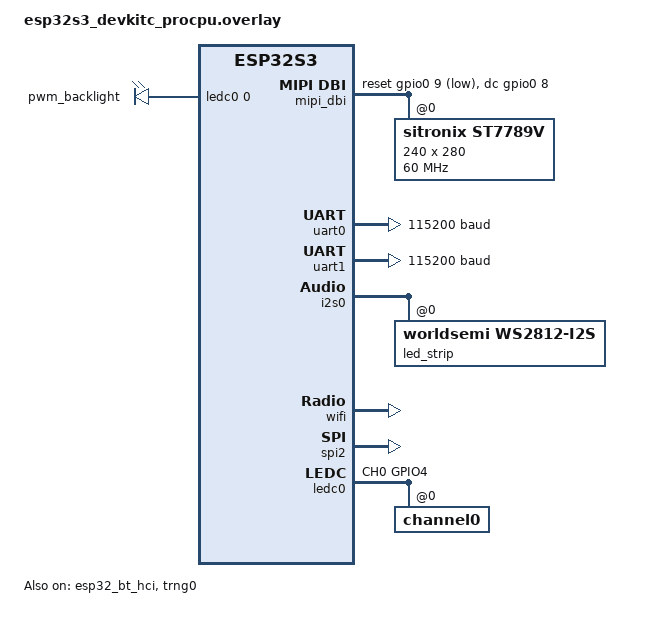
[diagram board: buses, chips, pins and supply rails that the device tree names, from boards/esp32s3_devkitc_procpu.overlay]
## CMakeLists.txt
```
# SPDX-License-Identifier: Apache-2.0

# 设定CMake最低版本门槛
cmake_minimum_required(VERSION 3.20.0)

# 告诉 Zephyr 在哪里找自定义的设备树绑定文件
# list(APPEND DTC_OVERLAY_FILE "${CMAKE_CURRENT_SOURCE_DIR}/esp32s3_devkitc_procpu.overlay")

# 设置自定义设备树绑定文件 (Bindings) 的搜索根目录。
# ${CMAKE_CURRENT_SOURCE_DIR} 指的是当前 CMakeLists.txt 所在的文件夹路径。
# 这行代码告诉 Zephyr 编译器：“除了去内核找硬件定义，也去我当前的项目目录下找找（通常是 dts/bindings 目录）”。
# 这样你写的 custom,sh1106.yaml 才能被系统识别。
set(DTS_ROOT ${CMAKE_CURRENT_SOURCE_DIR})

# 引入 Zephyr 编译框架的核心包。
# REQUIRED 表示这个包是必须的，找不到就直接报错停止。
# HINTS $ENV{ZEPHYR_BASE} 是给编译器一个“线索”，告诉它去环境变量 ZEPHYR_BASE 指向的路径找 Zephyr。
# 执行完这一行后，Zephyr 的所有编译规则、库文件、驱动框架都会被加载进你的项目中。
find_package(Zephyr REQUIRED HINTS $ENV{ZEPHYR_BASE})

# 定义当前项目的名称。
# 这里将项目命名为 "application"。这个名字会影响最终生成的二进制文件名（如 application.elf）。
# 它必须放在 find_package(Zephyr ...) 之后，因为 Zephyr 需要先初始化环境才能支持后续的项目定义。
project(application)

# 添加应用程序私有的头文件目录
# PRIVATE 表示这个 include 路径只对当前 app target 有效
target_include_directories(app PRIVATE
    include
    drivers/include
)

# 添加所有源文件到应用程序目标
target_sources(app PRIVATE
    src/main.c
    # src/memory_thread.c
    src/led_thread.c
    src/button_thread.c
    # src/bt_beacon_thread.c
    # src/bt_ibeacon_thread.c
    # src/bt_broadcaster_thread.c
    # src/bt_bthome_sensor_thread.c
    # src/bt_peripheral_thread.c
    src/bt_peripheral_nus_thread.c
    src/lcd_lvgl_thread.c
    src/wifi_weather_thread.c
    src/fonts/weather_chinese_font.c
    src/images/zephyr_200x116.c
    src/images/cyberpunk_240x280.c
    # src/lvgl_benchmark_thread.c        # [可选] LVGL 官方性能测试 (需同时启用 prj.conf 中的 CONFIG_LV_USE_DEMO_BENCHMARK)
)

# [LVGL Widgets Demo] 收集上游 LVGL 仓库中的 demo 源文件
# Zephyr 的 LVGL 模块只编译核心库, demo 的 .c 文件需要手动加入 target_sources
# lv_demos.c 是伞形文件, 根据 CONFIG_LV_USE_DEMO_WIDGETS 用 #if 条件包含各子文件
# file(GLOB_RECURSE LVGL_WIDGETS_SOURCES
#     # [伞形文件] 根据 Kconfig 决定编译哪些 demo (必须首先包含)
#     ${ZEPHYR_LVGL_MODULE_DIR}/demos/lv_demos.c
#     # [Widgets 主文件] 创建 TabView 容器 + 4 个 Tab 页面 + 自动幻灯片定时器
#     ${ZEPHYR_LVGL_MODULE_DIR}/demos/widgets/lv_demo_widgets.c
#     # [4 个子页面] 每个 Tab 对应一个独立的功能页面
#     ${ZEPHYR_LVGL_MODULE_DIR}/demos/widgets/lv_demo_widgets_shop.c
#     ${ZEPHYR_LVGL_MODULE_DIR}/demos/widgets/lv_demo_widgets_analytics.c
#     ${ZEPHYR_LVGL_MODULE_DIR}/demos/widgets/lv_demo_widgets_profile.c
#     ${ZEPHYR_LVGL_MODULE_DIR}/demos/widgets/lv_demo_widgets_components.c
#     # [图片资源] 预编译的 RGBA 像素数组, 链接到 Flash .rodata 段
#     ${ZEPHYR_LVGL_MODULE_DIR}/demos/widgets/assets/img_lvgl_logo.c
#     ${ZEPHYR_LVGL_MODULE_DIR}/demos/widgets/assets/img_clothes.c
#     ${ZEPHYR_LVGL_MODULE_DIR}/demos/widgets/assets/img_demo_widgets_avatar.c
#     ${ZEPHYR_LVGL_MODULE_DIR}/demos/widgets/assets/img_demo_widgets_needle.c
# )
# target_sources(app PRIVATE ${LVGL_WIDGETS_SOURCES})

# (可选) 链接所需的 Zephyr 库
# 正确的链接方式：只需要链接到 'zephyr' 目标
# target_link_libraries(app PRIVATE
#     zephyr
# )
```

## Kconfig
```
# ESP32-S3 DevKitC 应用级 Kconfig 入口
#
# 此文件作为 Zephyr Kconfig 的主入口点，在引入 Zephyr 官方配置后
# 提供应用级的 Kconfig 选项覆盖。
#
# 注意：ESP32-S3 (Xtensa) 架构默认不选中 HAS_FLASH_LOAD_OFFSET，
# 但 MCUboot 集成需要通过 USE_DT_CODE_PARTITION 来获取代码分区偏移。
# 这里参考 Telink TLSR951X 的做法添加默认值。

source "Kconfig.zephyr"

# 工作区修复：Xtensa (ESP32-S3) 架构缺少 HAS_FLASH_LOAD_OFFSET
# 当启用 MCUboot 时，BOOTLOADER_MCUBOOT 会 select USE_DT_CODE_PARTITION，
# 但 USE_DT_CODE_PARTITION 定义在 if HAS_FLASH_LOAD_OFFSET 条件块中。
# 此默认值确保 MCUboot 模式下 HAS_FLASH_LOAD_OFFSET 自动为 y。
config HAS_FLASH_LOAD_OFFSET
	default y if BOOTLOADER_MCUBOOT
```

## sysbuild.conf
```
# ==============================================================================
# SYSBUILD 全局多镜像组织配置文件
# ==============================================================================

# 告诉系统我们要启用 MCUboot 引导
SB_CONFIG_BOOTLOADER_MCUBOOT=y
```

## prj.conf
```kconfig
#
# Kernel & System (内核与系统基础)
#
# 定义系统时钟滴答的频率
CONFIG_SYS_CLOCK_TICKS_PER_SEC=1000
# 详细注释：v4.4.0 推荐使用 picolibc 以获得更小的 Flash 占用
CONFIG_PICOLIBC=y
# LVGL初始化或文件系统操作会复用main stack，因此需要增加 main stack size
CONFIG_MAIN_STACK_SIZE=6144
# 开启 Zephyr 的输入子系统
CONFIG_INPUT=y
# 初始化任务栈（用特定字节填充，用于监测栈使用量）
CONFIG_INIT_STACKS=y

#
# ==========================================================
# 第一部分：Console (控制台) - 解决“信息从哪发出来”
# ==========================================================
# 启用控制台基础功能
CONFIG_CONSOLE=y
# 启用早期控制台支持（内核启动初期的日志输出）
CONFIG_EARLY_CONSOLE=y

# 【关键点】必须为 y！
# 它是内核启动早期（Shell还没启动时）打印 Zephyr 版本信息的唯一通道。
# 如果设为 n，你将看不到 "*** Booting Zephyr OS ***" 这一行。
CONFIG_UART_CONSOLE=y

# 允许 printk 函数将信息发送到控制台
CONFIG_STDOUT_CONSOLE=y

# ==========================================================
# 第二部分：Logging (日志) - 解决“系统发生了什么”
# ==========================================================
# 启用日志系统
CONFIG_LOG=y

# 设置日志的显示模式
# 由于我们要用 Shell 来显示日志，所以禁用掉原始的 UART 直接输出模式，
# 防止日志和 Shell 的字符在屏幕上打架（乱码）。
CONFIG_LOG_BACKEND_UART=n

# 允许 printk 输出的信息也被当作日志处理
CONFIG_LOG_PRINTK=y

# 日志级别设置（4 是最高级别 INFO，能看到大部分信息）
CONFIG_LOG_MAX_LEVEL=4
CONFIG_LOG_DEFAULT_LEVEL=3

# ==========================================================
# 第三部分：Shell (外壳) - 解决“如何与开发板交互”
# ==========================================================
# 启用 Shell 功能
CONFIG_SHELL=y
CONFIG_SHELL_BACKENDS=y

# Shell 命令行线程栈大小
CONFIG_SHELL_STACK_SIZE=6144

# 启用串口作为 Shell 的后端（让你可以通过串口助手输入命令）
CONFIG_SHELL_BACKEND_SERIAL=y

# 启用 Shell 的日志后端
# 作用：让 Shell 接管 Log 系统的输出。
# 开启后，当系统产生日志时，Shell 会整齐地把它打印出来，
# 并且不会打断你正在输入的命令行（它会自动处理换行和光标）。
CONFIG_SHELL_LOG_BACKEND=y

# 设置 Shell 提示符，你在串口看到的就会是 my_board:~$
CONFIG_SHELL_PROMPT_UART="zephyr:~$ "

# 启用 HEX 文件输出，解决 west flash --runner openocd 的报错
CONFIG_BUILD_OUTPUT_HEX=y

#
# Core Drivers: Serial/UART (核心驱动：串行/UART)
#
# 启用串行子系统
CONFIG_SERIAL=y

# 启用浮点支持，以便在日志中打印浮点数
CONFIG_CBPRINTF_FP_SUPPORT=y

#
# 启用 SPI RAM 支持
# 
# 1. 开启外部 RAM 总支持
CONFIG_ESP_SPIRAM=y
# 2. 必须指定是八线(Octal)模式（16MB 型号通常是 Octal 1.8V）
CONFIG_SPIRAM_MODE_OCT=y
# 3. 设置速度（80MHz 是常见的安全选择，160MHz 可能不稳定）
CONFIG_SPIRAM_SPEED_80M=y
# 3. 设置容量 (16MB = 16777216 字节)
# CONFIG_ESP_SPIRAM_SIZE=16777216
# 4. 将 SPI RAM 用作系统内存的一部分（启用后，malloc 等函数可以使用 SPI RAM）
# CONFIG_ESP_SPIRAM_HEAP_SIZE=8388608
# 6. 可选：启动时进行内存测试，确保硬件连接没问题
# CONFIG_ESP_SPIRAM_MEMTEST=y

# 开启堆内存运行时状态统计功能（不开启的话，sys_heap_runtime_stats_get 会无法获取数据）
CONFIG_SYS_HEAP_RUNTIME_STATS=y

# 
# MCUboot 核心引导配置
# 
# 告诉 Zephyr 内核：当前应用程序是运行在 MCUboot 引导程序之上的
# 开启后，系统会自动处理好固件在 Flash 中的地址偏移（例如自动偏移到 0x20000）
# CONFIG_BOOTLOADER_MCUBOOT=y

# 
# 底层 Flash 驱动与存储支持（固件管理器的依赖项）
# 
# 开启物理 Flash 的底层驱动支持
CONFIG_FLASH=y
# 开启 Flash 的页布局（Page Layout）支持，以便系统能按块擦写 Flash
CONFIG_FLASH_PAGE_LAYOUT=y
# 开启流式 Flash 写入驱动（重要！用来彻底解决之前 STREAM_FLASH=n 导致的警告）
CONFIG_STREAM_FLASH=y
# 开启 Flash 地图映射管理，用于精准识别存储分区（Slot 0 / Slot 1）
CONFIG_FLASH_MAP=y

# 
# 固件管理器与 MCUboot 运行时联动
# 
# 开启应用层的固件镜像管理器（用于读取/验证固件的版本头信息）
CONFIG_IMG_MANAGER=y
# 开启专属于 MCUboot 的镜像管理实现（解决 choice 选项悬空以及 FOOTER_SIZE 警告）
CONFIG_MCUBOOT_IMG_MANAGER=y

# 
# 关闭保守的自动检测，榨干 32MB 八线 Flash 的极限性能
# 
# 关闭自动检测（省下 900 字节 IRAM，且解锁 DTR 限制）
CONFIG_ESPTOOLPY_FLASH_MODE_AUTO_DETECT=n
# 强制开启八线Octal Flash支持
CONFIG_ESPTOOLPY_OCT_FLASH=y
# 强制开启最高速的 DTR（双倍速率）采样模式
CONFIG_ESPTOOLPY_FLASH_SAMPLE_MODE_DTR=y
# 强制指定 Flash 大小为 32MB
CONFIG_ESPTOOLPY_FLASHSIZE_32MB=y

#
# Core Drivers: DMA (直接内存访问)
#
# 启用 DMA 核心支持
CONFIG_DMA=y

#
# Core Drivers: GPIO (通用输入/输出)
#
# 启用 GPIO 核心支持
CONFIG_GPIO=y

#
# Core Drivers: I2C
#
# 启用 I2C 核心支持
# CONFIG_I2C=y
# 开启软件模拟 I2C 驱动
# CONFIG_I2C_GPIO=y

#
# Core Drivers: Standard SPI
#
# 启用标准 SPI 核心支持 (如果需要连接 SPI 传感器/屏幕)
CONFIG_SPI=y
# 注意: SPI2 DMA (GDMA) 已在 overlay 中关闭 — 开启后导致黑屏+串口失效
# 原因可能是 GDMA 通道与 I2S0(Ch3) 的仲裁冲突, 或 PSRAM→GDMA→SPI2 路径问题
# 当前使用 CPU PIO 模式 (逐字节推 FIFO), 稳定性优先, 性能可通过 flush_thread 补偿
# CONFIG_SPI_ESP32_INTERRUPT=y

#
# Core Drivers: I2S (集成音频接口)
#
# I2S 用于 WS2812 LED strip 波形生成 (通过 worldsemi,ws2812-i2s 驱动)
CONFIG_I2S=y

#
# Core Drivers: PWM (脉宽调制)
#
CONFIG_PWM=y

#
# Core Drivers: RTC (实时时钟)
#
# 启用 RTC 核心支持
# CONFIG_RTC=y
# 启用 RTC 闹钟功能
# CONFIG_RTC_ALARM=y

#
# Core Drivers: LED (发光二极管)
#
# 启用 LED 核心驱动框架
# CONFIG_LED=y
CONFIG_LED_STRIP=y

# ==========================================================
# Core Drivers: Bluetooth (蓝牙)
# ==========================================================
# 启用蓝牙子系统
CONFIG_BT=y
# 启用安全管理协议
CONFIG_BT_SMP=y
# 配置为蓝牙广播角色
CONFIG_BT_BROADCASTER=y
# 配置为蓝牙外设角色
CONFIG_BT_PERIPHERAL=y
# 启用隐私功能
CONFIG_BT_PRIVACY=y

# 蓝牙设备名称
CONFIG_BT_DEVICE_NAME="ESP32S3_BLE"
# 允许动态修改名称
CONFIG_BT_DEVICE_NAME_DYNAMIC=y
# 动态名称最大长度（设置为纯数字）
CONFIG_BT_DEVICE_NAME_MAX=64
# 设备外观（833代表心率计）
CONFIG_BT_DEVICE_APPEARANCE=833

# 基础 GATT 服务
CONFIG_BT_DIS=y
CONFIG_BT_BAS=y
CONFIG_BT_HRS=y
CONFIG_BT_IAS=y
CONFIG_BT_CTS=y
CONFIG_BT_CTS_HELPER_API=y

# 启用 Zephyr 的 NUS（Nordic UART Service）蓝牙服务
CONFIG_BT_ZEPHYR_NUS=y

# 将 Host 层的连接发送上下文数量从默认值改为 12
CONFIG_BT_CONN_TX_MAX=12
# 建议同时将 ACL 缓存数量也对齐
CONFIG_BT_BUF_ACL_TX_COUNT=12

# 系统配置
# 增加工作队列栈大小（设置为纯数字）
CONFIG_SYSTEM_WORKQUEUE_STACK_SIZE=4096

# ==========================================================
# Core Drivers: NET (网络协议栈)
# ==========================================================
# 启用NET子系统

# 开启 Zephyr 核心网络通用协议栈支持
CONFIG_NETWORKING=y
# 开启测试用随机数生成器
CONFIG_TEST_RANDOM_GENERATOR=y

# 网络发送线程栈大小 (2048 字节)
CONFIG_NET_TX_STACK_SIZE=2048
# 网络接收线程栈大小 (2048 字节)
CONFIG_NET_RX_STACK_SIZE=2048

# 接收网络包结构体的最大数量
CONFIG_NET_PKT_RX_COUNT=10
# 发送网络包结构体的最大数量
CONFIG_NET_PKT_TX_COUNT=10
# 接收网络缓冲区的最大数量
CONFIG_NET_BUF_RX_COUNT=20
# 发送网络缓冲区的最大数量
CONFIG_NET_BUF_TX_COUNT=20
# 系统允许同时打开的最大网络上下文（套接字）数量
CONFIG_NET_MAX_CONTEXTS=10

# 开启 IPv4 协议支持（我们上网主力）
CONFIG_NET_IPV4=y
# 关闭 IPv6 协议支持（节省大量 RAM 空间！）
CONFIG_NET_IPV6=n
# 开启 TCP 传输层协议（用于后续 HTTP/MQTT）
CONFIG_NET_TCP=y
# 开启 DHCPv4 客户端（连接路由器后自动向其申请 IP）
CONFIG_NET_DHCPV4=y

# 开启网络 Shell 指令支持（如支持输入 net iface, net ping 等）
CONFIG_NET_SHELL=y
# 开启网络栈的内部日志输出输出
CONFIG_NET_LOG=y
# 开启网络流量统计统计（记录发了多少包，丢了多少包）
CONFIG_NET_STATISTICS=y
# 关闭定时自动在屏幕上打印统计报告
CONFIG_NET_STATISTICS_PERIODIC_OUTPUT=n

# 在新的锁设计中，向串口打印大量的扫描结果（WiFi Scan）会给系统的事件队列造成巨大的时间压力。
# 所以，在周围路由器非常密集的拥挤环境中，需要使用更高的超时时间和更大的队列深度。
# 事件队列超时时间放宽到 5000 毫秒
CONFIG_NET_MGMT_EVENT_QUEUE_TIMEOUT=5000
# 事件队列深度扩大到 16
CONFIG_NET_MGMT_EVENT_QUEUE_SIZE=16

# 开启动态域名解析功能（DNS Resolver）
CONFIG_DNS_RESOLVER=y
# 允许系统最多同时保存2个DNS服务器（一个主，一个备）
CONFIG_DNS_RESOLVER_MAX_SERVERS=2
# 允许通过 DHCP 自动从路由器获取 DNS 服务器的 IP地址
CONFIG_DNS_SERVER_IP_ADDRESSES=y

# ==========================================================
# Core Drivers: Wifi
# ==========================================================
# 启用Wifi子系统

# 开启底层 Wi-Fi 硬件驱动支持
CONFIG_WIFI=y
# 设置 Wi-Fi 日志级别为错误（只显示错误信息，减少日志干扰）
CONFIG_WIFI_LOG_LEVEL_ERR=y
# 启用 Wi-Fi Shell 命令，允许通过 Shell 交互式管理 Wi-Fi 连接（扫描、连接、状态查询等）
CONFIG_NET_L2_WIFI_SHELL=y

# ==========================================================
# Core Drivers: SNTP (简单网络时间协议)
# ==========================================================
# 启用 SNTP 客户端库（用于从 NTP 服务器获取精确的网络时间）
# SNTP 的超时时间在 C 代码中通过 sntp_ctx_obj.timeout 动态设置
CONFIG_SNTP=y

# ==========================================================
# Core Drivers: Socket DNS (增强 DNS 查询能力)
# ==========================================================
# 增加额外 DNS 查询次数 (类型为 int，取值 0~2)
# 当 DNS 响应只包含 CNAME 时，允许解析器额外发起查询以获取最终 A 记录
CONFIG_DNS_RESOLVER_ADDITIONAL_QUERIES=2

# ==========================================================
# Core Libraries: JSON (轻量级 JSON 解析库)
# ==========================================================
# 启用 Zephyr 内置 JSON 解析库（用于解析天气 API 返回的 JSON 响应）
CONFIG_JSON_LIBRARY=y

# Core dump 是在程序崩溃时保留的内存快照
# CONFIG_DEBUG_COREDUMP=y
# CONFIG_DEBUG_COREDUMP_BACKEND_LOGGING=y

#
# ==========================================================
# LCD & LVGL (液晶显示屏 + 图形界面)
# ==========================================================
# 启用显示子系统
CONFIG_DISPLAY=y
# 启用 MIPI DBI 模式 C (SPI 模拟) — 自动被 ST7789V 驱动选中
CONFIG_MIPI_DBI=y

# 启用 LVGL 图形库
CONFIG_LVGL=y
# 颜色深度使用 16 位 RGB565 (匹配 ST7789V 硬件格式)
CONFIG_LV_COLOR_DEPTH_16=y
# 启用 LVGL 内部日志
CONFIG_LV_USE_LOG=y
# LVGL 内存池大小 (从系统堆分配，用于 LVGL 内部对象管理)
# Widgets Demo 至少需要 38KB (编译器内置检查: LV_MEM_SIZE < 38KB 报错)
# 设为 48KB 留出安全余量, 内存池放在 PSRAM (CONFIG_LV_Z_MEMORY_POOL_CUSTOM_SECTION=y)
CONFIG_LV_Z_MEM_POOL_SIZE=65536
# ===== LVGL 渲染缓冲区 (性能关键) =====
# 渲染缓冲区 = 屏幕总像素的 100% (全帧缓冲)
# 240×280×2 字节 = 131KB 单缓冲, 262KB 双缓冲
# 放入 PSRAM (16MB) — 完全不占用宝贵的内部 SRAM
CONFIG_LV_Z_VDB_SIZE=100
# 双缓冲: LVGL 渲染到 buf0 的同时, SPI 从 buf1 刷屏
# 消除画面撕裂 (tearing), 是视觉流畅度的最大提升项
CONFIG_LV_Z_DOUBLE_VDB=y
# 缓冲区从静态数组分配 (编译时决定)
CONFIG_LV_Z_BUFFER_ALLOC_STATIC=y
# ★★★ 关键: 将渲染缓冲区放入 PSRAM ★★★
# ESP32-S3 default.ld 第 1049 行已内置: KEEP(*(.lvgl_buf*))
# 开启后 __attribute__((section(".lvgl_buf"))) → 链接器自动放入 ext_dram_seg
CONFIG_LV_Z_VDB_CUSTOM_SECTION=y
# ★★★ 关键: 将 LVGL 内存池放入 PSRAM ★★★
# ESP32-S3 default.ld 第 1051 行已内置: KEEP(*(.lvgl_heap*))
CONFIG_LV_Z_MEMORY_POOL_CUSTOM_SECTION=y
# 在应用启动前自动初始化 LVGL 库
CONFIG_LV_Z_AUTO_INIT=y

# ===== LVGL 独立渲染工作队列 (性能关键) =====
# 开启后 LVGL 在专用高优先级线程中运行 lv_timer_handler(),
# 应用线程不再需要手动调用, 且不会被低优先级任务阻塞
CONFIG_LV_Z_RUN_LVGL_ON_WORKQUEUE=y
# 工作队列优先级: 5 (高于大部分应用线程, 保证 UI 流畅)
CONFIG_LV_Z_LVGL_WORKQUEUE_PRIORITY=5
# 工作队列栈大小: 4096 (足够 LVGL 渲染使用)
CONFIG_LV_Z_LVGL_WORKQUEUE_STACK_SIZE=4096

# 启用 16 位颜色字节交换 (RGB565 格式)
# 【关键】ESP32 是小端序 (Little Endian)，而 ST7789 屏幕期望大端序 (Big Endian) 数据。
# 不开启此选项时：像素数据按 [高8位][低8位] 顺序发送，屏幕端解析颠倒 →
#                 现象：屏幕能显示图像，但颜色完全错误（红蓝颠倒、花屏、杂色）
# 开启此选项后：LVGL 在发送前自动交换每 2 字节的高低顺序 →
#                 发送 [低8位][高8位]，屏幕正确解析为 RGB565
# 总结：只要 SPI 屏颜色不对，第一个检查的就是这个选项！
CONFIG_LV_COLOR_16_SWAP=y

# ===== LVGL Widgets (按需启用，节约 Flash) =====
CONFIG_LV_USE_LABEL=y
CONFIG_LV_USE_BUTTON=y
CONFIG_LV_USE_IMAGE=y
CONFIG_LV_USE_CANVAS=y
CONFIG_LV_FONT_MONTSERRAT_14=y
# Widgets Demo 界面使用多种字号 (标题/正文/图表标注)
# Montserrat 字体族: 12=小字标签, 16=正文字号, 18/20=标题, 24=大标题
CONFIG_LV_FONT_MONTSERRAT_12=y
CONFIG_LV_FONT_MONTSERRAT_16=y
CONFIG_LV_FONT_MONTSERRAT_18=y
CONFIG_LV_FONT_MONTSERRAT_20=y
CONFIG_LV_FONT_MONTSERRAT_24=y

# [赛博朋克时钟] 48号巨字时间 + 28号温度数字
CONFIG_LV_FONT_MONTSERRAT_28=y
CONFIG_LV_FONT_MONTSERRAT_48=y

# [已替换] 改用自定义 weather_chinese_font (src/fonts/weather_chinese_font.c)
# CONFIG_LV_FONT_SOURCE_HAN_SANS_SC_16_CJK=y

# ===== LVGL 官方 Demo 构建 =====
# LV_BUILD_DEMOS 是编译 lv_demos.c 的门控开关 (伞形文件)
CONFIG_LV_BUILD_DEMOS=y
# Widgets Demo: 4 个 Tab 页 (Shop/Analytics/Profile/Components)
# 自动 8 秒轮播切换, 是 LVGL 9 自带的视觉最丰富的官方 Demo
CONFIG_LV_USE_DEMO_WIDGETS=y
# 系统监控: 为 perf monitor 提供真实 CPU 空闲率数据
# 如果不启用, perf monitor 会回退到测量 lv_timer_handler 耗时来估算 CPU
CONFIG_LV_USE_SYSMON=y
# [已关闭] 右下角 FPS/CPU 性能监视器 (赛博朋克时钟不需要)
# CONFIG_LV_USE_PERF_MONITOR=y
# 刷新周期: 默认 33ms(30FPS) → 10ms(100FPS) 解除帧率软上限
CONFIG_LV_DEF_REFR_PERIOD=10
# 独立刷新线程: 渲染和 SPI 刷屏并行, 消除等待
CONFIG_LV_Z_FLUSH_THREAD=y
```

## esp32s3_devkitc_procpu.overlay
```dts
/* esp32s3_devkitc_procpu.overlay */

/* 直接包含适配 16MB Flash + 8MB PSRAM 的定义 */
// #include <espressif/esp32s3/esp32s3_wroom_n16r8.dtsi>

/* 包含必要的头文件，这些头文件里定义了硬件信号 ID */
#include <espressif/esp32s3/esp32s3_common.dtsi>
#include <zephyr/dt-bindings/pinctrl/esp32s3-pinctrl.h>
#include <zephyr/dt-bindings/pinctrl/esp32s3-gpio-sigmap.h>
#include <zephyr/dt-bindings/led/led.h>

/* 自定义 Flash + PSRAM 的大小 */
/* 32MB flash */
&flash0 {
	reg = <0x0 DT_SIZE_M(32)>;
};

/* 16MB psram */
&psram0 {
	size = <DT_SIZE_M(16)>;
};

/ {
    chosen {
        /* 核心：告诉 Zephyr 用哪个串口跑 Shell */
        zephyr,shell-uart = &uart1;
        zephyr,console = &uart1;
    };

    aliases {
        led-strip = &led_strip;
    };

    // leds {
    //     compatible = "gpio-leds";
    //     test_gpio38: led_0 {
    //         /* GPIO38 在 Zephyr ESP32 映射中通常属于 gpio1 的第 6 号引脚 (32 + 6 = 38) */
    //         gpios = <&gpio1 6 GPIO_ACTIVE_HIGH>;
    //         label = "Test GPIO38";
    //     };
    // };
};

/* 引脚复用配置：将 GPIO38 映射为 SPI3 的数据输出信号 (ID 68) */
&pinctrl {
    spim3_ws2812_default: spim3_ws2812_default {
        group1 {
            /* * ESP32_PINMUX(1, 6, 68) 的含义：
             * 1: GPIO 分组 1 (引脚 32-53)
             * 6: 组内索引 6 (32 + 6 = 38)
             * 68: SPI3_D_OUT (MOSI) 的信号 ID
             */
            pinmux = <ESP32_PINMUX(1, 6, 68)>;
            /* 核心修正：显式开启输出使能，并关闭偏置电阻 */
            output-enable;
            bias-disable;
        };
    };
};

/* 确保 uart0 节点是启用状态 */
&uart0 {
    status = "okay";
    current-speed = <115200>;
};

&uart1 {
	status = "okay";
	current-speed = <115200>;
	pinctrl-0 = <&uart1_default>;
	pinctrl-names = "default";
};

&i2s0_default {
	group1 {
		pinmux = <I2S0_O_SD_GPIO38>;
	};
};

i2s_led: &i2s0 {
	status = "okay";

	dmas = <&dma 3>;
	dma-names = "tx";

	led_strip: ws2812@0 {
		compatible = "worldsemi,ws2812-i2s";

		reg = <0>;
		chain-length = <1>;
		color-mapping = <LED_COLOR_ID_GREEN
				 LED_COLOR_ID_RED
				 LED_COLOR_ID_BLUE>;
		reset-delay = <500>;
	};
};

&dma {
	status = "okay";
};
```

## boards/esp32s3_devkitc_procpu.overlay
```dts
/* esp32s3_devkitc_procpu.overlay */

/* 包含必要的头文件，这些头文件里定义了硬件信号 ID */
#include <espressif/esp32s3/esp32s3_common.dtsi>
#include <zephyr/dt-bindings/pinctrl/esp32s3-pinctrl.h>
#include <zephyr/dt-bindings/pinctrl/esp32s3-gpio-sigmap.h>
#include <zephyr/dt-bindings/led/led.h>
/* [LCD] 引入 MIPI DBI 和显示面板的 DT 常量定义 */
#include <zephyr/dt-bindings/mipi_dbi/mipi_dbi.h>
#include <zephyr/dt-bindings/display/panel.h>
/* [PWM] 引入 PWM 宏定义 (PWM_HZ, PWM_POLARITY_NORMAL 等) */
#include <zephyr/dt-bindings/pwm/pwm.h>

/*
 * ESP32-S3 外部 32MB 八线 Flash (经典 Swap 模式) 分区表覆盖定义
 * 通过精准标签引用 (&)，直接强行重写物理区间，100% 避免 Label 重复冲突
 */
&flash0 {
    /* 1. 锁死外部物理 Flash 总大小为 32MB (十六进制上限 0x2000000) */
    reg = <0x0 DT_SIZE_M(32)>;

    /* 2. 深入到 partitions 容器内部，通过路径覆盖将地址与节点名一字不差地绑死 */
    partitions {
        compatible = "fixed-partitions";
        #address-cells = <0x1>;
        #size-cells = <0x1>;

		/* 🌟 核心杀招：使用绝对路径或节点名，彻底将官方旧定义里的“不合规节点”物理蒸发！ */
		/delete-node/ partition@0;
		/delete-node/ partition@10000;
		/delete-node/ partition@20000;
		/delete-node/ partition@170000;
		/delete-node/ partition@2c0000;
		/delete-node/ partition@330000;
		/delete-node/ partition@3a0000;
		/delete-node/ partition@3a8000;
		/delete-node/ partition@3b0000;
		/delete-node/ partition@3e0000;
		/delete-node/ partition@3ff000;

        /* 1. MCUboot 引导程序区：系统启动的第一跳，负责校验和加载固件 */
        boot_partition: partition@0 {
            label = "mcuboot";
            reg = <0x0 DT_SIZE_K(64)>; /* 占用 64KB */
        };

        /* 2. 系统保留区：可能用于存放分区表索引、系统标志位或必要的硬件配置参数 */
        sys_partition: partition@10000 {
            label = "sys";
            reg = <0x10000 DT_SIZE_K(64)>; /* 占用 64KB */
        };

        /* 3. 主核心 (ProCPU) 的主程序区 (Slot 0) */
        slot0_partition: partition@20000 {
            label = "image-0";
            reg = <0x20000 DT_SIZE_K(12096)>; /* 约 11.8MB */
        };

        /* 4. 主核心 (ProCPU) 的升级备份区 (Slot 1) */
        slot1_partition: partition@bf0000 {
            label = "image-1";
            reg = <0xbf0000 DT_SIZE_K(12096)>; /* 大小与 Slot 0 必须对称 */
        };

        /* 5. AppCPU (副核心) 的主程序区 */
        slot0_appcpu_partition: partition@17c0000 {
            label = "image-0-appcpu";
            reg = <0x17c0000 DT_SIZE_K(4032)>; /* 约 3.9MB */
        };

        /* 6. AppCPU (副核心) 的升级备份区 */
        slot1_appcpu_partition: partition@1bb0000 {
            label = "image-1-appcpu";
            reg = <0x1bb0000 DT_SIZE_K(4032)>;
        };

        /* 7. LP-Core (低功耗核心) 的主程序区 */
        slot0_lpcore_partition: partition@1fa0000 {
            label = "image-0-lpcore";
            reg = <0x1fa0000 DT_SIZE_K(32)>; /* 32KB，通常用于超轻量级代码 */
        };

        /* 8. LP-Core (低功耗核心) 的升级备份区 */
        slot1_lpcore_partition: partition@1fa8000 {
            label = "image-1-lpcore";
            reg = <0x1fa8000 DT_SIZE_K(32)>;
        };

        /* 9. 数据存储区：用于存放文件系统 (如 LittleFS/FATFS) 或 NVS 参数 */
        storage_partition: partition@1fb0000 {
            label = "storage";
            reg = <0x1fb0000 DT_SIZE_K(192)>; /* 192KB */
        };

        /* 10. 临时交换区：OTA 升级过程中，MCUboot 使用该区域进行镜像搬运/恢复 */
        scratch_partition: partition@1fe0000 {
            label = "image-scratch";
            reg = <0x1fe0000 DT_SIZE_K(124)>; /* 124KB */
        };

        /* 11. 崩溃转储区：系统发生异常 (Panic/Crash) 时保存现场信息 */
        coredump_partition: partition@1fff000 {
            label = "coredump";
            reg = <0x1fff000 DT_SIZE_K(4)>; /* 4KB，用于存核心寄存器快照 */
        };
    };
};

/*
 * ESP32-S3 外部 16MB 八线 PSRAM
 */
&psram0 {
	size = <DT_SIZE_M(16)>;
};

/ {
    chosen {
        /* 核心：告诉 Zephyr 用哪个串口跑 Shell */
        zephyr,shell-uart = &uart1;
        zephyr,console = &uart1;
        /* 明确指定主应用的代码存储分区！ */
        zephyr,code-partition = &slot0_partition;
        /* 核心：告诉 LVGL 用哪个显示设备 */
        zephyr,display = &st7789v;
    };

    aliases {
        led-strip = &led_strip;
        /* [PWM 背光] 通过别名让 C 代码用 PWM_DT_SPEC_GET 获取 PWM 设备 */
        pwm-backlight = &pwm_bl;
    };

    /*
     * [LCD 显示] ST7789V SPI 显示屏 (240x280) 配置
     * 通过 MIPI DBI SPI 框架驱动
     *
     * 硬件接线:
     *   SCLK → GPIO12, MOSI → GPIO11, CS → GPIO10
     *   DC   → GPIO8,  RST  → GPIO9
     *   BLK  → GPIO4 (背光 PWM)
     *   VCC  → 3.3V,   GND  → GND
     *
     * 注意事项:
     *   - DC 引脚: 高电平=数据, 低电平=命令
     *   - RST 引脚: 低电平复位 (GPIO_ACTIVE_LOW)
     *   - write-only 表示只写不读，节省引脚和代码
     *   - y-offset = 20: 因为 ST7789 内部 RAM 是 240x320,
     *     240x280 的显示区域需要垂直偏移居中
     */
    mipi_dbi {
        compatible = "zephyr,mipi-dbi-spi";
        /*
         * [SPI 总线] 使用 ESP32-S3 的 FSPI (SPI2)
         * 默认引脚: CS=GPIO10, MOSI=GPIO11, SCLK=GPIO12
         * 不需要 MISO (只写模式)
         */
        spi-dev = <&spi2>;
        /*
         * [DC 引脚] 数据/命令选择线
         * gpio0 表示 GPIO 控制器 0 (管理 GPIO0~GPIO31)
         * 8 表示 GPIO8
         * GPIO_ACTIVE_HIGH: 高电平传输数据，低电平传输命令
         */
        dc-gpios = <&gpio0 8 GPIO_ACTIVE_HIGH>;
        /*
         * [RST 引脚] 硬件复位线
         * GPIO_ACTIVE_LOW: 低电平触发复位，正常工作为高电平
         */
        reset-gpios = <&gpio0 9 GPIO_ACTIVE_LOW>;
        /* [只写模式] ST7789 不需要读回像素数据，设为只写优化性能 */
        write-only;
        #address-cells = <1>;
        #size-cells = <0>;

        /*
         * [ST7789V 显示面板子节点]
         * compatible = "sitronix,st7789v" 匹配 Zephyr 内置驱动
         * reg = <0>: 使用 SPI CS0 (GPIO10)
         */
        st7789v: st7789v@0 {
            compatible = "sitronix,st7789v";
            reg = <0>;
            /*
             * [SPI 时钟] 20MHz
             * ST7789 数据手册支持最高 62.5MHz (写周期)
             * 使用 20MHz 是稳定可靠的选择，线太长可降至 10MHz
             */
            /*
             * [SPI 时钟] 40MHz (性能优化)
             * ST7789 写周期最小 66ns (约 15MHz 理论值)
             * 实测 40MHz 稳定运行，画面流畅无撕裂
             * 如果画面花屏/闪屏，降回 20MHz
             */
            /*
             * [SPI 时钟] 60MHz (性能极限)
             * ST7789 写周期 66ns → 理论 15MHz
             * 实际模组可超频到 60-80MHz 稳定工作
             * 如花屏/闪屏, 降回 40MHz
             */
            mipi-max-frequency = <60000000>;
            /*
             * [SPI 模式] 4 线模式:
             *   - CS:  片选 (GPIO10)
             *   - DC:  数据/命令 (GPIO8)
             *   - SCLK: 时钟 (GPIO12)
             *   - MOSI: 数据 (GPIO11)
             * 3 线模式只用 3 根线 (DC 复用)，4 线更稳定
             */
            mipi-mode = "MIPI_DBI_MODE_SPI_4WIRE";
            /* [分辨率] 240x280 像素 */
            width = <240>;
            height = <280>;
            /* [水平偏移] 通常从 0 开始 */
            x-offset = <0>;
            /*
             * [垂直偏移] ST7789 内部 GRAM 是 240x320
             * 对于 240x280 的物理面板，显示区域通常需要偏移
             * y-offset = (320 - 280) / 2 = 20 像素居中
             * 如果画面上下有错位，请调整这个值
             */
            y-offset = <20>;

            pixel-format = <PANEL_PIXEL_FORMAT_RGB_565>;

            /* ===== 以下为 ST7789 初始化时序参数 ===== */
            /* 这些参数来自 ST7789V 数据手册的推荐值 */
            /* ===== 以下面板时序参数来自 Pandora 已验证配置 ===== */
            vcom = <0x3F>;                    /* VCOM 电压 (pandora 值) */
            gctrl = <0x05>;                   /* 门极控制 (pandora 值) */
            vrhs = <0x0F>;                    /* VRH 设置 (pandora 值) */
            vdvs = <0x20>;                    /* VDV 设置 */
            mdac = <0x00>;                    /* MADCTL: 默认扫描方向 */
            gamma = <0x01>;                   /* Gamma 曲线选择 */
            // colmod = <0x05>;                  /* COLMOD: [像素格式] RGB565 (16 位色) */
            lcm = <0x2c>;                     /* LCM 控制 */
            porch-param = [0c 0c 00 33 33];   /* 前后廊参数 (5 字节) */
            cmd2en-param = [5a 69 02 01];     /* Command2 使能参数 (4 字节) */
            pwctrl1-param = [a4 a1];          /* 电源控制 1 (2 字节) */
            pvgam-param = [D0 05 09 09 08 14 28 33 3F 07 13 14 28 30]; /* 正极性 Gamma (pandora 值) */
            nvgam-param = [D0 05 09 09 08 03 24 32 32 3B 14 13 28 2F]; /* 负极性 Gamma (pandora 值) */
            ram-param = [00 f0];              /* RAM 控制参数 (2 字节) */
            rgb-param = [cd 08 14];           /* RGB 接口控制参数 (3 字节) */
        };
    };

    /*
     * [PWM 背光] LEDC PWM 控制 GPIO4 → LCD BLK
     *
     * 使用 ESP32-S3 的 LEDC 控制器，通道 0，定时器 0
     * PWM_HZ(250): 250Hz 频率 (周期 4ms)，高于人眼闪烁感知阈值 (~50Hz)
     *               低频 PWM 可以减少 EMI 同时保持无闪烁感
     * PWM_POLARITY_NORMAL: 高电平点亮背光
     *
     * 对应 C 代码中:
     *   PWM_DT_SPEC_GET(DT_ALIAS(pwm_backlight))
     *   返回 &ledc0 通道 0 的 PWM 规格，用于 pwm_set_pulse_dt()
     */
    pwmleds {
        compatible = "pwm-leds";
        status = "okay";

        pwm_bl: pwm_bl {
            pwms = <&ledc0 0 PWM_HZ(250) PWM_POLARITY_NORMAL>;
            label = "pwm_backlight";
        };
    };

    // leds {
    //     compatible = "gpio-leds";
    //     test_gpio38: led_0 {
    //         /* GPIO38 在 Zephyr ESP32 映射中通常属于 gpio1 的第 6 号引脚 (32 + 6 = 38) */
    //         gpios = <&gpio1 6 GPIO_ACTIVE_HIGH>;
    //         label = "Test GPIO38";
    //     };
    // };
};

/*
 * [LEDC 背光引脚复用] 将 GPIO4 映射为 LEDC 通道 0 的 PWM 输出
 *
 * LEDC_CH0_GPIO4 的定义位于:
 *   zephyr/include/zephyr/dt-bindings/pinctrl/esp32s3-pinctrl.h
 *   #define LEDC_CH0_GPIO4 ESP32_PINMUX(4, ESP_NOSIG, ESP_LEDC_LS_SIG_OUT0)
 *
 * output-enable: GPIO4 设为推挽输出模式
 */
&pinctrl {
    ledc0_default: ledc0_default {
        group1 {
            pinmux = <LEDC_CH0_GPIO4>;
            output-enable;
        };
    };
};

/* 确保 uart0 节点是启用状态 */
&uart0 {
    status = "okay";
    current-speed = <115200>;
};

&uart1 {
	status = "okay";
	current-speed = <115200>;
	pinctrl-0 = <&uart1_default>;
	pinctrl-names = "default";
};

&i2s0_default {
	group1 {
		pinmux = <I2S0_O_SD_GPIO38>;
	};
};

i2s_led: &i2s0 {
	status = "okay";

	dmas = <&dma 3>;
	dma-names = "tx";

	led_strip: ws2812@0 {
		compatible = "worldsemi,ws2812-i2s";

		reg = <0>;
		chain-length = <1>;
		color-mapping = <LED_COLOR_ID_GREEN
				        LED_COLOR_ID_RED
				        LED_COLOR_ID_BLUE>;
		reset-delay = <500>;
	};
};

&dma {
	status = "okay";
};

&wifi {
    status = "okay";
};

&esp32_bt_hci {
    status = "okay";
};

&trng0 {
    status = "okay";
};

/*
 * [SPI2] FSPI 总线 — 用于驱动 ST7789 LCD
 * 使用默认引脚映射:
 *   CS   = GPIO10 (FSPICS0)
 *   MOSI = GPIO11 (FSPID)
 *   SCLK = GPIO12 (FSPICLK)
 *   MISO = GPIO13 (FSPIQ) — LCD 是只写的，这个引脚实际未使用
 */
&spi2 {
    status = "okay";
    pinctrl-0 = <&spim2_default>;
    pinctrl-names = "default";
};

/*
 * [LEDC PWM 控制器] ESP32-S3 的 LED 控制模块
 *
 * 配置说明:
 *   - 通道 0 (channel0@0): 绑定到 GPIO4，用于 LCD 背光调光
 *   - timer = <0>: 使用定时器 0 作为时钟源
 *     LEDC 有 4 个独立定时器 (0~3)，每个定时器可以有不同频率
 *
 * 使用方式 (C 代码):
 *   const struct pwm_dt_spec pwm_bl =
 *       PWM_DT_SPEC_GET(DT_ALIAS(pwm_backlight));
 *   pwm_set_pulse_dt(&pwm_bl, duty_ns);  // 设置占空比
 */
&ledc0 {
    status = "okay";
    pinctrl-0 = <&ledc0_default>;
    pinctrl-names = "default";
    #address-cells = <1>;
    #size-cells = <0>;

    /*
     * [通道 0] LEDC 通道 0 — 输出到 GPIO4
     * reg = <0x0>: 通道号 (必须匹配 pinctrl 中的 LEDC_CH0_GPIO4)
     * timer = <0>: 使用定时器 0 (0~3)
     */
    channel0@0 {
        reg = <0x0>;
        timer = <0>;
    };
};
```

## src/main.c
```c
#include <zephyr/kernel.h>
#include <zephyr/logging/log.h>

LOG_MODULE_REGISTER(MAIN, LOG_LEVEL_INF);

int main(void)
{
    // 仅仅打印一行启动信息即可
    LOG_INF("=== Zephyr System Power Up ===");

    // 无需调用 start_xxx_thread()，因为它们已经自动运行了
    
    // 关键：进入永久休眠，把所有的 CPU 资源和栈空间释放给那些重要线程
    while (1) {
        k_sleep(K_FOREVER);
    }
    return 0;
}
```

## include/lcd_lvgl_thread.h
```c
#ifndef LCD_LVGL_THREAD_H
#define LCD_LVGL_THREAD_H

#include <zephyr/types.h>

/**
 * @brief LVGL 显示线程的全局控制变量声明
 *
 * 这些变量由 LCD/LVGL 线程维护，可供其他线程 (如 BLE) 读取或修改，
 * 实现跨线程的显示内容控制。
 */

/* [显示亮度] 背光亮度 0~100，0=关闭, 100=最亮 */
extern volatile int g_lcd_brightness;

/* [显示状态] 当前 LVGL 是否正在运行 */
extern volatile bool g_lvgl_ready;

/**
 * @brief LVGL 线程将由 K_THREAD_DEFINE 自动创建并启动，
 *        无需手动调用任何启动函数。
 *        此处仅声明 API 供外部模块 (如 Shell、BLE) 引用。
 */

#endif /* LCD_LVGL_THREAD_H */
```

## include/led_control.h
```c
#ifndef LED_CONTROL_H
#define LED_CONTROL_H

// 定义呼吸灯亮度上限(0-255)，移到头文件方便蓝牙和LED线程共同使用
#define LIGHT_MAX 0x40

/**
 * @brief 定义 LED 的显示模式枚举
 */
typedef enum {
    LED_MODE_OFF = 0,       /* 关闭所有 LED 灯 */
    LED_MODE_BREATHE_RED,   /* 红色呼吸灯 */
    LED_MODE_BREATHE_GREEN, /* 绿色呼吸灯 */
    LED_MODE_BREATHE_BLUE   /* 蓝色呼吸灯 */
} led_mode_t;

/* 全局 LED 模式变量（volatile 防止编译器过度优化） */
extern volatile led_mode_t g_led_mode;

/* 【新增】全局 LED 实时亮度变量，由 LED 线程更新，蓝牙线程读取 */
extern volatile int g_led_brightness;

#endif /* LED_CONTROL_H */
```

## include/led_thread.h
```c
#ifndef LED_THREAD_H
#define LED_THREAD_H

#include <zephyr/types.h>

/**
 * @brief 启动 LED 控制线程。
 */
void start_led_thread(void);

// 可以在这里声明其他供外部调用的 API
//例如：void set_led_state(bool on);

#endif // LED_THREAD_H
```

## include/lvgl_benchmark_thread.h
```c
/*
 * [LVGL Benchmark 测试线程] 头文件
 *
 * 此线程由 K_THREAD_DEFINE 自动创建并延迟 3 秒启动。
 * 无需手动调用任何启动函数。
 *
 * 测试完成后线程自动退出, 屏幕保持测试结果界面。
 * 按下开发板的 RST 键可重启回到正常 UI。
 */

#ifndef LVGL_BENCHMARK_THREAD_H
#define LVGL_BENCHMARK_THREAD_H

#include <zephyr/types.h>

/**
 * @brief Benchmark 线程将在系统启动 3 秒后自动运行
 *
 * 通过 K_THREAD_DEFINE 中的启动延迟参数 (3000ms) 实现。
 * 本头文件仅作文档用途 — 不需要额外的初始化调用。
 */

#endif /* LVGL_BENCHMARK_THREAD_H */
```

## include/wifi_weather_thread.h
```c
/*
 * [WiFi + 天气 + 时间线程] 全局变量声明
 *
 * 本头文件声明 wifi_weather_thread.c 中定义的全局变量，
 * 供其他线程（如 LCD 显示线程）读取当前的网络状态、时间和天气信息。
 *
 * 使用方式:
 *   #include "wifi_weather_thread.h"
 *   // if (g_wifi_connected) { 显示 WiFi 图标 }
 *   // LOG_INF("当前温度: %d°C", g_temperature);
 */

#ifndef WIFI_WEATHER_THREAD_H
#define WIFI_WEATHER_THREAD_H

#include <zephyr/kernel.h>   /* [内核] volatile bool, atomic_t 等类型 */

#ifdef __cplusplus
extern "C" {
#endif

/* ==================== 网络状态变量 ==================== */

/* [WiFi 连接标志] true=已连接路由器并获取到 IP 地址 */
extern volatile bool g_wifi_connected;

/* [WiFi IP 地址字符串] 点分十进制格式，如 "192.168.1.100" */
extern volatile char g_wifi_ip_addr[16];

/* ==================== RTC 实时时钟 (硬件定时器驱动) ==================== */

/* [RTC 基准] SNTP 同步时的 Unix 时间戳 (北京时间 UTC+8) */
extern volatile uint64_t g_rtc_base_unix;

/* [RTC 基准] SNTP 同步时的系统 uptime (毫秒) */
extern volatile uint64_t g_rtc_base_uptime;

/* [RTC 同步标志] true=已建立 RTC 时间基准 */
extern volatile bool g_rtc_synced;

/* ==================== 时间同步变量 (兼容旧接口) ==================== */

/* [时间同步标志] true=已通过 SNTP 成功获取网络时间 */
extern volatile bool g_time_synced;

/* [当前时间] 时:分:秒 (北京时间 UTC+8)
 * 注意: 启用 RTC 后这些值由 LVGL 1Hz 回调实时计算 */
extern volatile int g_current_hour;
extern volatile int g_current_minute;
extern volatile int g_current_second;

/* [当前日期] 年/月/日 (北京时间 UTC+8) */
extern volatile int g_current_year;
extern volatile int g_current_month;
extern volatile int g_current_day;

/* [当前星期] 0=周日, 1=周一 ... 6=周六 */
extern volatile int g_current_weekday;

/* ==================== 天气信息变量 ==================== */

/* [天气同步标志] true=已成功获取天气数据 */
extern volatile bool g_weather_ready;

/* [当前温度] 单位：摄氏度(°C)，范围通常 -50 ~ 50 */
extern volatile int g_temperature;

/* [WMO 天气代码] 用于确定天气图标和描述
 *  0=晴天, 1/2/3=多云, 45/48=雾, 51-57=小雨, 61-67=雨
 *  71-77=雪, 80-82=阵雨, 95-99=雷暴
 *  完整对照表: https://www.nodc.noaa.gov/archive/arc0021/0002199/1.1/data/0-data/HTML/WMO-CODE/WMO4677.HTM
 */
extern volatile int g_weather_code;

/* [天气描述字符串] 中文天气描述，如 "晴天"、"多云"、"小雨" 等 */
extern volatile char g_weather_desc[32];

/* [风速] 单位：km/h */
extern volatile int g_wind_speed;

/* ==================== 蓝牙 & 电池状态变量 ==================== */

/* [蓝牙连接标志] true=蓝牙已连接对端设备 */
extern volatile bool g_bluetooth_connected;

/* [电池电量] 百分比(0~100)，100 表示满电 */
extern volatile int g_battery_level;

/* [空气湿度] 百分比(0~100)，单位 %RH */
extern volatile int g_humidity;

/* ==================== 线程 ID 声明 ==================== */

/* [线程 ID] wifi_weather 线程的 ID，供其他代码引用
 * 注意: K_THREAD_DEFINE 宏将其定义为 const k_tid_t */
extern const k_tid_t wifi_weather_tid;

#ifdef __cplusplus
}
#endif

#endif /* WIFI_WEATHER_THREAD_H */
```

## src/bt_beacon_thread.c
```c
#include <zephyr/types.h>
#include <stddef.h>
#include <zephyr/sys/printk.h>
#include <zephyr/sys/util.h>

/* 引入 Zephyr 蓝牙核心栈头文件 */
#include <zephyr/bluetooth/bluetooth.h>
#include <zephyr/bluetooth/hci.h>

/* 从 Kconfig 配置中获取设备名称（通常在 prj.conf 中定义） */
#define DEVICE_NAME CONFIG_BT_DEVICE_NAME
#define DEVICE_NAME_LEN (sizeof(DEVICE_NAME) - 1)

/* 
 * 定义广播数据 (Advertising Data, AD)
 * 这里的数据格式遵循 Eddystone 规范
 */
static const struct bt_data ad[] = {
    /* 标志位：LE General Discoverable Mode & 不支持 BR/EDR (经典蓝牙) */
	BT_DATA_BYTES(BT_DATA_FLAGS, BT_LE_AD_NO_BREDR),
    
    /* 16位服务 UUID：0xFEAA 代表 Eddystone */
	BT_DATA_BYTES(BT_DATA_UUID16_ALL, 0xaa, 0xfe),
    
    /* 服务数据 (Service Data)：包含实际的 URL 内容 */
	BT_DATA_BYTES(BT_DATA_SVC_DATA16,
		      0xaa, 0xfe, /* Eddystone UUID (重复以符合格式) */
		      0x10,       /* 帧类型：Eddystone-URL */
		      0x00,       /* 0米处的校准发射功率 (TX Power) */
		      0x00,       /* URL 前缀：http://www. */
		      'z', 'e', 'p', 'h', 'y', 'r',
		      'p', 'r', 'o', 'j', 'e', 'c', 't',
		      0x08)       /* 后缀映射：0x08 代表 .org */
};

/* 
 * 定义扫描响应数据 (Scan Response Data, SD)
 * 当手机等主设备主动扫描该 Beacon 时，会返回这段额外信息
 */
static const struct bt_data sd[] = {
    /* 返回完整的设备名称 */
	BT_DATA(BT_DATA_NAME_COMPLETE, DEVICE_NAME, DEVICE_NAME_LEN),
};

/* 蓝牙初始化完成后的回调函数 */
static void bt_ready(int err)
{
	bt_addr_le_t addr = {0};
	size_t count = 1;

	if (err) {
		printk("蓝牙初始化失败 (错误码 %d)\n", err);
		return;
	}

	printk("蓝牙初始化成功\n");

	/* 
     * 开始广播
     * BT_LE_ADV_NCONN_IDENTITY: 非连接广播（不可连接），使用身份地址
     * ad: 广播包内容
     * sd: 扫描响应包内容
     */
	err = bt_le_adv_start(BT_LE_ADV_NCONN_IDENTITY, ad, ARRAY_SIZE(ad),
			      sd, ARRAY_SIZE(sd));
	if (err) {
		printk("广播启动失败 (错误码 %d)\n", err);
		return;
	}

	/* 获取并打印当前设备正在使用的蓝牙 MAC 地址 */
	bt_id_get(&addr, &count);
	printk("Beacon 已启动，广播地址为 %s\n", bt_addr_le_str(&addr));
}

/**
 * @brief 蓝牙线程入口函数
 * 
 * @param p1, p2, p3 线程参数（由 K_THREAD_DEFINE 传入，此处未使用）
 */
void bt_thread_entry(void *p1, void *p2, void *p3)
{
	int err;

	printk("正在启动 Beacon 示例程序\n");

	/* 
     * 异步启动蓝牙子系统
     * 初始化完成后会自动调用 bt_ready 回调函数
     */
	err = bt_enable(bt_ready);
	if (err) {
		printk("蓝牙启动失败 (错误码 %d)\n", err);
	}
    
	return;
}

/* 线程配置参数 */
#define BT_STACK_SIZE 4096  // 线程栈大小（单位：字节）
#define BT_PRIORITY 11      // 线程优先级（数字越大优先级越低）

/**
 * @brief 定义并自动启动线程
 * 
 * 参数依次为：线程 ID, 栈大小, 入口函数, 参数1, 参数2, 参数3, 优先级, 选项, 启动延迟
 */
K_THREAD_DEFINE(bluetooth_tid, BT_STACK_SIZE, 
                bt_thread_entry, NULL, NULL, NULL,
                BT_PRIORITY, 0, 0);
```

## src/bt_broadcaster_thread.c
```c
#include <zephyr/types.h>
#include <stddef.h>
#include <zephyr/sys/printk.h>
#include <zephyr/sys/util.h>

/* 蓝牙核心头文件 */
#include <zephyr/bluetooth/bluetooth.h>
#include <zephyr/bluetooth/hci.h>


/* 从 Kconfig 配置中获取设备名称（通常在 prj.conf 中定义） */
#define DEVICE_NAME CONFIG_BT_DEVICE_NAME
#define DEVICE_NAME_LEN (sizeof(DEVICE_NAME) - 1)

/* 
 * 自定义厂商数据 (Manufacturer Specific Data)
 * 前两个字节 0xff, 0xff 通常是厂商 ID（这里是测试用的伪 ID）
 * 第三个字节 0x00 是我们要动态改变的数据计数器
 */
static uint8_t mfg_data[] = { 0xff, 0xff, 0x00 };

/* 广播数据数组 */
// static const struct bt_data ad[] = {
//     /* 
//      * 使用 BT_DATA 宏引用上面的 mfg_data 数组
//      * 类型为 BT_DATA_MANUFACTURER_DATA（厂商自定义数据）
//      */
// 	BT_DATA(BT_DATA_MANUFACTURER_DATA, mfg_data, 3),
// };
static const struct bt_data ad[] = {
    /* 1. 标志位：必带，否则手机可能拒收*/
    // BT_DATA_BYTES(BT_DATA_FLAGS, (BT_LE_AD_GENERAL | BT_LE_AD_NO_BREDR)),
    /* 2. 你的自定义数据*/
    BT_DATA(BT_DATA_MANUFACTURER_DATA, mfg_data, 3),
    /* 3. 把名字也放进广播包，方便识别*/
    BT_DATA(BT_DATA_NAME_COMPLETE, DEVICE_NAME, DEVICE_NAME_LEN),
};

/**
 * @brief 蓝牙线程入口函数
 * 
 * @param p1, p2, p3 线程参数（由 K_THREAD_DEFINE 传入，此处未使用）
 */
void bt_thread_entry(void *p1, void *p2, void *p3)
{
	int err;

	printk("正在启动广播者 (Broadcaster)...\n");

	/* 
     * 初始化蓝牙子系统
     * 传入 NULL 表示【同步初始化】：程序会阻塞在这里，直到蓝牙硬件准备就绪
     */
	err = bt_enable(NULL);
	if (err) {
		printk("蓝牙初始化失败 (错误码 %d)\n", err);
		return;
	}

	printk("蓝牙初始化成功\n");

	/* 1. 先启动广播，不要在启动前睡觉 */
	err = bt_le_adv_start(BT_LE_ADV_NCONN, ad, ARRAY_SIZE(ad), NULL, 0);
	if (err) {
		printk("Start failed %d\n", err);
		return;
	}

	/* 2. 然后再进入循环只更新数据，不要停掉广播 */
	while (1) {
		k_msleep(1000);
		mfg_data[2]++;
		// 使用专门的更新接口，比先停再开更稳定
		bt_le_adv_update_data(ad, ARRAY_SIZE(ad), NULL, 0); 
		printk("Updated data: 0x%02X\n", mfg_data[2]);
	}

	/* 进入应用主循环 */
	// do {
	// 	/* 等待 1000 毫秒 */
	// 	k_msleep(1000);

	// 	printk("正在发送广播数据: 0x%02X\n", mfg_data[2]);

	// 	/* 
    //      * 启动广播
    //      * BT_LE_ADV_NCONN: 不可连接广播
    //      * ad: 包含我们的 mfg_data
    //      * NULL, 0: 此处没有设置扫描响应数据
    //      */
	// 	err = bt_le_adv_start(BT_LE_ADV_NCONN, ad, ARRAY_SIZE(ad),
	// 			      NULL, 0);
	// 	if (err) {
	// 		printk("广播启动失败 (错误码 %d)\n", err);
	// 		return;
	// 	}

	// 	/* 广播持续 1000 毫秒 */
	// 	k_msleep(1000);

	// 	/* 停止广播：关闭射频发射，节省电量 */
	// 	err = bt_le_adv_stop();
	// 	if (err) {
	// 		printk("广播停止失败 (错误码 %d)\n", err);
	// 		return;
	// 	}

	// 	/* 
    //      * 核心逻辑：修改数据
    //      * 直接修改引用的 mfg_data 数组内容
    //      * 下次调用 bt_le_adv_start 时，发出的就是更新后的值
    //      */
	// 	mfg_data[2]++;

	// } while (1); // 死循环，不停地 开启-等待-关闭-修改-循环
    
	return;
}

/* 线程配置参数 */
#define BT_STACK_SIZE 4096  // 线程栈大小（单位：字节）
#define BT_PRIORITY 11      // 线程优先级（数字越大优先级越低）

/**
 * @brief 定义并自动启动线程
 * 
 * 参数依次为：线程 ID, 栈大小, 入口函数, 参数1, 参数2, 参数3, 优先级, 选项, 启动延迟
 */
K_THREAD_DEFINE(bluetooth_tid, BT_STACK_SIZE, 
                bt_thread_entry, NULL, NULL, NULL,
                BT_PRIORITY, 0, 0);
```

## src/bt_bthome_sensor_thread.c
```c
/* 
 * BTHome 传感器模板示例 
 */

#include <zephyr/bluetooth/bluetooth.h>
#include <zephyr/bluetooth/uuid.h>

/* 定义 BTHome 服务数据长度和 UUID */
#define SERVICE_DATA_LEN        9
#define SERVICE_UUID            0xfcd2      /* BTHome 官方分配的 16位 UUID */
#define IDX_TEMPL               4           /* 存储温度低字节在数组中的索引 */
#define IDX_TEMPH               5           /* 存储温度高字节在数组中的索引 */

/* 
 * 自定义广播参数：
 * 1. BT_LE_ADV_OPT_USE_IDENTITY: 使用设备真实的身份地址。
 * 2. BT_GAP_ADV_SLOW_INT_MIN/MAX: 使用较慢的广播频率（省电模式）。
 */
#define ADV_PARAM BT_LE_ADV_PARAM(BT_LE_ADV_OPT_USE_IDENTITY, \
				  BT_GAP_ADV_SLOW_INT_MIN, \
				  BT_GAP_ADV_SLOW_INT_MAX, NULL)

/* 
 * BTHome 数据载荷格式：
 * 字节 0-1: UUID (0xfcd2)
 * 字节 2: 0x40 (BTHome V2 标志)
 * 字节 3: 0x02 (数据类型：温度)
 * 字节 4-5: 温度数值 (Little Endian, 单位 0.01°C)
 * 字节 6: 0x03 (数据类型：湿度)
 * 字节 7-8: 湿度数值 (Little Endian, 单位 0.01%)
 */
static uint8_t service_data[SERVICE_DATA_LEN] = {
	BT_UUID_16_ENCODE(SERVICE_UUID),
	0x40,
	0x02,	/* Temperature ID */
	0xc4,	/* 19.88°C 的低字节 (示例初值) */
	0x00,   /* 高字节 */
	0x03,	/* Humidity ID */
	0xbf,	/* 50.55% 的低字节 */
	0x13,   /* 高字节 */
};

/* 构造广播包 */
static struct bt_data ad[] = {
    /* 标志位：通用可发现 */
	BT_DATA_BYTES(BT_DATA_FLAGS, BT_LE_AD_GENERAL | BT_LE_AD_NO_BREDR),
    /* 设备名称：从 prj.conf 获取 */
	BT_DATA(BT_DATA_NAME_COMPLETE, CONFIG_BT_DEVICE_NAME, sizeof(CONFIG_BT_DEVICE_NAME) - 1),
    /* 核心：16位服务数据 (Service Data)，存放 BTHome 载荷 */
	BT_DATA(BT_DATA_SVC_DATA16, service_data, ARRAY_SIZE(service_data))
};

/**
 * @brief 蓝牙线程入口函数
 * 
 * @param p1, p2, p3 线程参数（由 K_THREAD_DEFINE 传入，此处未使用）
 */
void bt_thread_entry(void *p1, void *p2, void *p3)
{
	int err;
	int temp = 0; // 模拟温度变量

	printk("正在启动 BTHome 传感器模板...\n");

	/* 初始化蓝牙（同步模式） */
	err = bt_enable(NULL);
	if (err) {
		printk("初始化失败 (err %d)\n", err);
		return;
	}

	/* 开启广播 */
	err = bt_le_adv_start(ADV_PARAM, ad, ARRAY_SIZE(ad), NULL, 0);
	if (err) {
		printk("广播失败 (err %d)\n", err);
		return;
	}

	for (;;) {
		/* 
         * 模拟数据逻辑：
         * BTHome 要求温度单位是 0.01°C，所以 25°C 要发 2500。
         * 2500 的十六进制是 0x09C4。
         */
		service_data[IDX_TEMPH] = (temp * 100) >> 8;   /* 取高 8 位 */
		service_data[IDX_TEMPL] = (temp * 100) & 0xff; /* 取低 8 位 */

		if (temp++ == 25) {
			temp = 0;
		}

		/* 
         * 关键 API：动态更新广播内容。
         * 此函数不需要停止广播再重新开启，能更平滑地切换数据。
         */
		err = bt_le_adv_update_data(ad, ARRAY_SIZE(ad), NULL, 0);
		if (err) {
			printk("更新失败 (err %d)\n", err);
		}

		/* 按照广播间隔进入睡眠，保持同步 */
		k_sleep(K_MSEC(BT_GAP_ADV_SLOW_INT_MIN));
	}
	return;
}

/* 线程配置参数 */
#define BT_STACK_SIZE 4096  // 线程栈大小（单位：字节）
#define BT_PRIORITY 11      // 线程优先级（数字越大优先级越低）

/**
 * @brief 定义并自动启动线程
 * 
 * 参数依次为：线程 ID, 栈大小, 入口函数, 参数1, 参数2, 参数3, 优先级, 选项, 启动延迟
 */
K_THREAD_DEFINE(bluetooth_tid, BT_STACK_SIZE, 
                bt_thread_entry, NULL, NULL, NULL,
                BT_PRIORITY, 0, 0);
```

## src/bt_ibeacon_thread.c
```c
/* iBeacon 示例 */

#include <zephyr/types.h>
#include <stddef.h>
#include <zephyr/sys/printk.h>
#include <zephyr/sys/util.h>

#include <zephyr/bluetooth/bluetooth.h>
#include <zephyr/bluetooth/hci.h>

/* 
 * 1米处的基准 RSSI 值（校准值）。
 * 0xc8 补码表示 -56 dBm。手机 App 根据这个参考值和接收到的实际信号强度来估算距离。
 */
#ifndef IBEACON_RSSI
#define IBEACON_RSSI 0xc8
#endif

/* 构造 iBeacon 广播包 */
static const struct bt_data ad[] = {
    /* 标志位：仅限蓝牙低功耗 (LE)，不支持经典蓝牙 (BR/EDR) */
	BT_DATA_BYTES(BT_DATA_FLAGS, BT_LE_AD_NO_BREDR),
    
    /* 核心：iBeacon 格式的厂商自定义数据 */
	BT_DATA_BYTES(BT_DATA_MANUFACTURER_DATA,
		      0x4c, 0x00, /* 1. Apple 公司 ID (0x004c)，小端序 */
		      0x02, 0x15, /* 2. 数据类型 (0x02) 和 剩余长度 (0x15 = 21 字节) */
		      /* 3. Proximity UUID (16 字节): 标识一个组织或区域 */
		      0x18, 0xee, 0x15, 0x16, /* UUID[15..12] */
		      0x01, 0x6b,             /* UUID[11..10] */
		      0x4b, 0xec,             /* UUID[9..8] */
		      0xad, 0x96,             /* UUID[7..6] */
		      0xbc, 0xb9, 0x6d, 0x16, 0x6e, 0x97, /* UUID[5..0] */
		      /* 4. Major (2 字节): 主编号，通常用于区分分店 */
		      0x00, 0x00, 
		      /* 5. Minor (2 字节): 次编号，通常用于区分具体货架或位置 */
		      0x00, 0x00, 
		      /* 6. Measured Power: 1米处的 RSSI 校准值 */
		      IBEACON_RSSI) 
};

/* 蓝牙就绪后的回调函数 */
static void bt_ready(int err)
{
	if (err) {
		printk("蓝牙初始化失败 (err %d)\n", err);
		return;
	}

	printk("蓝牙初始化成功\n");

	/* 
     * 开始广播：
     * BT_LE_ADV_NCONN: 不可连接广播 (iBeacon 只需要广播，不需要连接)
     */
	err = bt_le_adv_start(BT_LE_ADV_NCONN, ad, ARRAY_SIZE(ad),
			      NULL, 0);
	if (err) {
		printk("广播启动失败 (err %d)\n", err);
		return;
	}

	printk("iBeacon 已开始运行\n");
}

/**
 * @brief 蓝牙线程入口函数
 * 
 * @param p1, p2, p3 线程参数（由 K_THREAD_DEFINE 传入，此处未使用）
 */
void bt_thread_entry(void *p1, void *p2, void *p3)
{
	int err;

	printk("正在启动 iBeacon 演示...\n");

	/* 初始化蓝牙系统，初始化完成后会调用 bt_ready */
	err = bt_enable(bt_ready);
	if (err) {
		printk("蓝牙初始化启动失败 (err %d)\n", err);
	}
	return;
}

/* 线程配置参数 */
#define BT_STACK_SIZE 4096  // 线程栈大小（单位：字节）
#define BT_PRIORITY 11      // 线程优先级（数字越大优先级越低）

/**
 * @brief 定义并自动启动线程
 * 
 * 参数依次为：线程 ID, 栈大小, 入口函数, 参数1, 参数2, 参数3, 优先级, 选项, 启动延迟
 */
K_THREAD_DEFINE(bluetooth_tid, BT_STACK_SIZE, 
                bt_thread_entry, NULL, NULL, NULL,
                BT_PRIORITY, 0, 0);
```

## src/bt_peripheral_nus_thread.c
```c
/*
 * 这里的 NUS (Nordic UART Service) 是一个自定义服务，
 * 用于在蓝牙连接上模拟串口通信（RX/TX）。
 */

#include <zephyr/kernel.h>
#include <zephyr/bluetooth/bluetooth.h>
#include <zephyr/bluetooth/services/nus.h> // 核心：引入 NUS 服务头文件
#include <stdio.h>
#include "led_control.h"

#define DEVICE_NAME		CONFIG_BT_DEVICE_NAME
#define DEVICE_NAME_LEN		(sizeof(DEVICE_NAME) - 1)

/* 定义并初始化全局 LED 模式，默认开机为绿色呼吸灯，默认亮度为 0 */
volatile led_mode_t g_led_mode = LED_MODE_BREATHE_GREEN;
volatile int g_led_brightness = 0;

/* 广播数据：设备启动后，手机扫描到时看到的信息 */
static const struct bt_data ad[] = {
	/* 设置为通用可发现模式，不支持经典蓝牙 */
	BT_DATA_BYTES(BT_DATA_FLAGS, (BT_LE_AD_GENERAL | BT_LE_AD_NO_BREDR)),
	/* 设置广播中的设备名称 */
	BT_DATA(BT_DATA_NAME_COMPLETE, DEVICE_NAME, DEVICE_NAME_LEN),
};

/* 扫描响应数据：当手机请求更多信息时，设备回复的内容 */
static const struct bt_data sd[] = {
	/* 告知手机：本设备支持 NUS 服务（UUID 为 128 位） */
	BT_DATA_BYTES(BT_DATA_UUID128_ALL, BT_UUID_NUS_SRV_VAL),
};

/* 回调函数：当手机端开启或关闭“通知（Notification）”时触发 */
static void notif_enabled(bool enabled, void *ctx)
{
	ARG_UNUSED(ctx);
	// 如果 enabled 为 true，说明手机现在可以接收来自板子的数据了
	printk("%s() - %s\n", __func__, (enabled ? "Enabled" : "Disabled"));
}

/* 回调函数：当手机通过蓝牙发送数据给板子时，会调用此函数（相当于串口 RX） */
static void received(struct bt_conn *conn, const void *data, uint16_t len, void *ctx)
{
	ARG_UNUSED(conn);
	ARG_UNUSED(ctx);

	/* 打印接收到的数据长度和内容 */
	printk("%s() - Len: %d, Message: %.*s\n", __func__, len, len, (char *)data);

	/* 【新逻辑】解析手机发送过来的控制指令 */
	if (len > 0) {
		// 取出接收到的第一个字节（字符）
		char cmd = ((char *)data)[0]; 

		// 根据不同的字符，修改全局的 LED 模式变量
		switch (cmd) {
			case 'R':
			case 'r':
				g_led_mode = LED_MODE_BREATHE_RED;
				printk("蓝牙指令：切换为 [红色] 呼吸灯\n");
				break;
			case 'G':
			case 'g':
				g_led_mode = LED_MODE_BREATHE_GREEN;
				printk("蓝牙指令：切换为 [绿色] 呼吸灯\n");
				break;
			case 'B':
			case 'b':
				g_led_mode = LED_MODE_BREATHE_BLUE;
				printk("蓝牙指令：切换为 [蓝色] 呼吸灯\n");
				break;
			case '0':
				g_led_mode = LED_MODE_OFF;
				printk("蓝牙指令：[关闭] LED 灯\n");
				break;
			default:
				printk("未知的蓝牙指令: %c\n", cmd);
				break;
		}
	}
}

/* 将上面定义的两个回调函数注册到 NUS 结构体中 */
struct bt_nus_cb nus_listener = {
	.notif_enabled = notif_enabled,
	.received = received,
};

/**
 * @brief 蓝牙线程入口函数
 * 
 * @param p1, p2, p3 线程参数（由 K_THREAD_DEFINE 传入，此处未使用）
 */
void bt_thread_entry(void *p1, void *p2, void *p3)
{
	int err;

	printk("Sample - Bluetooth Peripheral NUS\n");

	/* 1. 注册 NUS 回调：告诉系统，如果收到数据或连接状态改变，找谁处理 */
	err = bt_nus_cb_register(&nus_listener, NULL);
	if (err) {
		printk("Failed to register NUS callback: %d\n", err);
		return ;
	}

	/* 2. 初始化蓝牙控制器和协议栈 */
	err = bt_enable(NULL);
	if (err) {
		printk("Failed to enable bluetooth: %d\n", err);
		return ;
	}

	/* 3. 开始广播
	 * BT_LE_ADV_CONN_FAST_1：使用较快的广播频率，方便手机快速发现
	 * ad: 广播数据；sd: 扫描响应数据
	 */
	err = bt_le_adv_start(BT_LE_ADV_CONN_FAST_1, ad, ARRAY_SIZE(ad), sd, ARRAY_SIZE(sd));
	if (err) {
		printk("Failed to start advertising: %d\n", err);
		return ;
	}

	printk("Initialization complete\n");

	/* 主循环：每隔 3 秒向手机发送一次LED状态 (相当于串口 TX) */
	while (true) {
		// 倒计时 3 秒
		k_sleep(K_SECONDS(3));

		//  将当前的模式枚举转换为字符串文字
		const char *color_str;
		switch (g_led_mode) {
			case LED_MODE_OFF:           color_str = "OFF";   break;
			case LED_MODE_BREATHE_RED:   color_str = "RED";   break;
			case LED_MODE_BREATHE_GREEN: color_str = "GREEN"; break;
			case LED_MODE_BREATHE_BLUE:  color_str = "BLUE";  break;
			default:                     color_str = "UNKNOWN"; break;
		}

		// 计算当前的占空比百分比
		// 公式：(当前亮度值 * 100) / 最大亮度值
		int duty_cycle = (g_led_brightness * 100) / LIGHT_MAX;

		// 组装超短文本，例如: "GREEN:45%\n"
		// 这样设计的好处是长度在 7 ~ 11 字节之间，远低于蓝牙默认的 20 字节限制！
		char tx_buffer[24];
		snprintf(tx_buffer, sizeof(tx_buffer), "%s:%d%%\n", color_str, duty_cycle);
		/*  发送动态组装好的状态数据到手机 */
		err = bt_nus_send(NULL, tx_buffer, strlen(tx_buffer));

		if (err < 0 && (err != -EAGAIN) && (err != -ENOTCONN)) {
			return ;
		} else if (err == 0) {
            printk("Data send success: %s", tx_buffer);
        }
	}

	return ;
}

/* 线程配置参数 */
#define BT_STACK_SIZE 4096  // 线程栈大小（单位：字节）
#define BT_PRIORITY 11      // 线程优先级（数字越大优先级越低）

/**
 * @brief 定义并自动启动线程
 * 
 * 参数依次为：线程 ID, 栈大小, 入口函数, 参数1, 参数2, 参数3, 优先级, 选项, 启动延迟
 */
K_THREAD_DEFINE(bluetooth_tid, BT_STACK_SIZE, 
                bt_thread_entry, NULL, NULL, NULL,
                BT_PRIORITY, 0, 0);
```

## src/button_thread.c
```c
#include <zephyr/kernel.h>
#include <zephyr/device.h>
#include <zephyr/drivers/gpio.h>
#include <zephyr/sys/util.h>
#include <zephyr/sys/printk.h>
#include <inttypes.h>
#include <zephyr/logging/log.h>

// 启用日志记录
LOG_MODULE_REGISTER(BUTTON_TASK, LOG_LEVEL_INF);

#define SLEEP_TIME_MS	1

/*
 * Get button configuration from the devicetree sw0 alias. This is mandatory.
 */
#define SW0_NODE	DT_ALIAS(sw0)
#if !DT_NODE_HAS_STATUS_OKAY(SW0_NODE)
#error "Unsupported board: sw0 devicetree alias is not defined"
#endif
static const struct gpio_dt_spec button = GPIO_DT_SPEC_GET_OR(SW0_NODE, gpios,
							      {0});
static struct gpio_callback button_cb_data;

/*
 * The led0 devicetree alias is optional. If present, we'll use it
 * to turn on the LED whenever the button is pressed.
 */
static struct gpio_dt_spec led = GPIO_DT_SPEC_GET_OR(DT_ALIAS(led0), gpios,
						     {0});

void button_pressed(const struct device *dev, struct gpio_callback *cb,
		    uint32_t pins)
{
	LOG_DBG("Button pressed at %" PRIu32 "\n", k_cycle_get_32());
}

/**
 * @brief 按钮线程入口函数
 * 
 * @param p1, p2, p3 线程参数（由 K_THREAD_DEFINE 传入，此处未使用）
 */
void button_thread_entry(void *p1, void *p2, void *p3)
{
	int ret;

	if (!gpio_is_ready_dt(&button)) {
		LOG_ERR("Error: button device %s is not ready\n",
		       button.port->name);
		return;
	}

	ret = gpio_pin_configure_dt(&button, GPIO_INPUT);
	if (ret != 0) {
		LOG_ERR("Error %d: failed to configure %s pin %d\n",
		       ret, button.port->name, button.pin);
		return;
	}

	ret = gpio_pin_interrupt_configure_dt(&button,
					      GPIO_INT_EDGE_TO_ACTIVE);
	if (ret != 0) {
		LOG_ERR("Error %d: failed to configure interrupt on %s pin %d\n",
			ret, button.port->name, button.pin);
		return;
	}

	gpio_init_callback(&button_cb_data, button_pressed, BIT(button.pin));
	gpio_add_callback(button.port, &button_cb_data);
	LOG_DBG("Set up button at %s pin %d\n", button.port->name, button.pin);

	if (led.port && !gpio_is_ready_dt(&led)) {
		LOG_ERR("Error %d: LED device %s is not ready; ignoring it\n",
		       ret, led.port->name);
		led.port = NULL;
	}
	if (led.port) {
		ret = gpio_pin_configure_dt(&led, GPIO_OUTPUT);
		if (ret != 0) {
			LOG_ERR("Error %d: failed to configure LED device %s pin %d\n",
			       ret, led.port->name, led.pin);
			led.port = NULL;
		} else {
			LOG_DBG("Set up LED at %s pin %d\n", led.port->name, led.pin);
		}
	}

	LOG_DBG("Press the button\n");
	if (led.port) {
		while (1) {
			/* If we have an LED, match its state to the button's. */
			int val = gpio_pin_get_dt(&button);

			if (val >= 0) {
				gpio_pin_set_dt(&led, val);
			}
			k_msleep(SLEEP_TIME_MS);
		}
	}
	return;
}

// 线程栈和定义
#define BUTTON_STACK_SIZE 1024
#define BUTTON_PRIORITY 12

K_THREAD_DEFINE(button_tid, BUTTON_STACK_SIZE, 
                button_thread_entry, NULL, NULL, NULL,
                BUTTON_PRIORITY, 0, 0);
```
